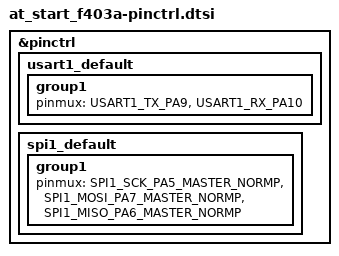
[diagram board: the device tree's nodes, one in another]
/*
 * Copyright (c) 2025, Maxjta
 * SPDX-License-Identifier: Apache-2.0
 */

#include <dt-bindings/pinctrl/at32f403av(g)xx-pinctrl.h>

&pinctrl {
	usart1_default: usart1_default {
		group1 {
			pinmux = <USART1_TX_PA9>, <USART1_RX_PA10>;
		};
	};
	spi1_default: spi1_default {
		group1 {
			pinmux = <SPI1_SCK_PA5_MASTER_NORMP>, <SPI1_MOSI_PA7_MASTER_NORMP>,
				 <SPI1_MISO_PA6_MASTER_NORMP>;
		};
	};
};
